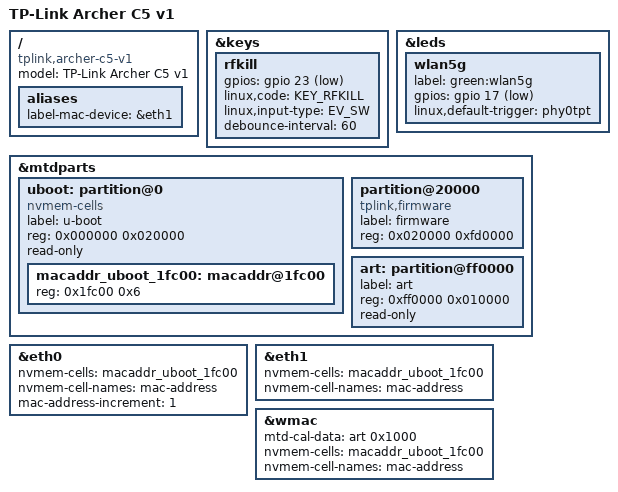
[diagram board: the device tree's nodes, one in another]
// SPDX-License-Identifier: GPL-2.0-or-later OR MIT

#include "qca9558_tplink_archer-c.dtsi"

/ {
	compatible = "tplink,archer-c5-v1", "qca,qca9558";
	model = "TP-Link Archer C5 v1";

	aliases {
		label-mac-device = &eth1;
	};
};

&keys {
	rfkill {
		gpios = <&gpio 23 GPIO_ACTIVE_LOW>;
		linux,code = <KEY_RFKILL>;
		linux,input-type = <EV_SW>;
		debounce-interval = <60>;
	};
};

&leds {
	wlan5g {
		label = "green:wlan5g";
		gpios = <&gpio 17 GPIO_ACTIVE_LOW>;
		linux,default-trigger = "phy0tpt";
	};
};

&mtdparts {
	uboot: partition@0 {
		label = "u-boot";
		reg = <0x000000 0x020000>;
		read-only;
	};

	partition@20000 {
		label = "firmware";
		reg = <0x020000 0xfd0000>;
		compatible = "tplink,firmware";
	};

	art: partition@ff0000 {
		label = "art";
		reg = <0xff0000 0x010000>;
		read-only;
	};
};

&eth0 {
	nvmem-cells = <&macaddr_uboot_1fc00>;
	nvmem-cell-names = "mac-address";
	mac-address-increment = <1>;
};

&eth1 {
	nvmem-cells = <&macaddr_uboot_1fc00>;
	nvmem-cell-names = "mac-address";
};

&wmac {
	mtd-cal-data = <&art 0x1000>;

	nvmem-cells = <&macaddr_uboot_1fc00>;
	nvmem-cell-names = "mac-address";
};

&uboot {
	compatible = "nvmem-cells";
	#address-cells = <1>;
	#size-cells = <1>;

	macaddr_uboot_1fc00: macaddr@1fc00 {
		reg = <0x1fc00 0x6>;
	};
};
